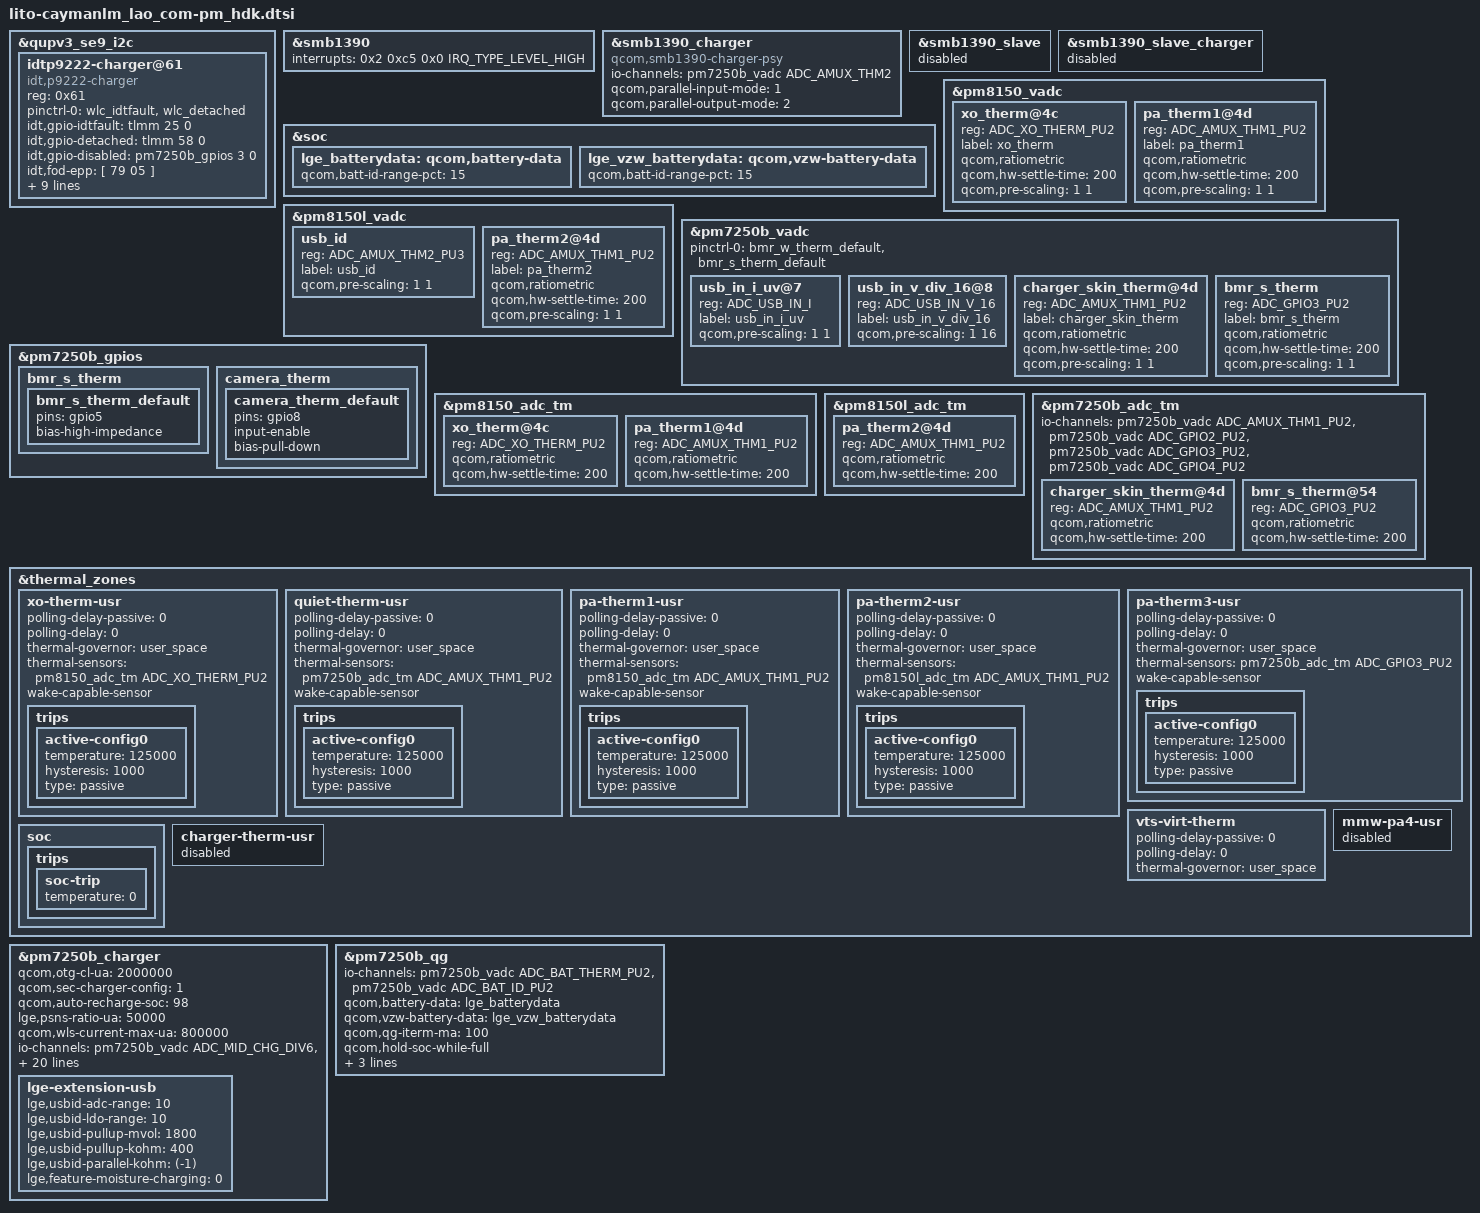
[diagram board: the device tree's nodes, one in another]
// SPDX-License-Identifier: GPL-2.0-only
/*
 * Copyright (c) 2018-2019, The Linux Foundation. All rights reserved.
 */

#include "../lito-caymanlm_common/lito-caymanlm_common-pm.dtsi"

&qupv3_se9_i2c {
	status = "ok";
	#include "../../../qcom/smb1390.dtsi"
};

&smb1390 {
	/delete-property/ interrupts;
	interrupts = <0x2 0xc5 0x0 IRQ_TYPE_LEVEL_HIGH>;
	status = "ok";
};

&smb1390_charger {
	compatible = "qcom,smb1390-charger-psy";
	io-channels = <&pm7250b_vadc ADC_AMUX_THM2>;
	io-channel-names = "cp_die_temp";
	qcom,parallel-input-mode = <1>; /* USBIN */
	qcom,parallel-output-mode = <2>; /* VBAT */
	status = "ok";
};

&smb1390_slave {
	status = "disabled";
};

&smb1390_slave_charger {
	status = "disabled";
};

&soc {
    lge_batterydata: qcom,battery-data {
        qcom,batt-id-range-pct = <15>;
        #include "../../battery_profile/LGE_BLT44_LGC_3450mAh.dtsi"
        #include "../../battery_profile/LGE_BLT47_ATL_4300mAh.dtsi"
        #include "../../battery_profile/LGE_BLT47F_ATL_4300mAh.dtsi"
        #include "../../battery_profile/LGE_BLT47_LGC_4300mAh.dtsi"
    };

     lge_vzw_batterydata: qcom,vzw-battery-data {
        qcom,batt-id-range-pct = <15>;
        #include "../../battery_profile/LGE_BLT47F_LGC_4000mAh.dtsi"
        #include "../../battery_profile/LGE_BLT47_LGC_4000mAh.dtsi"
    };
};

&pm8150_vadc {
	xo_therm@4c {
		reg = <ADC_XO_THERM_PU2>;
		label = "xo_therm";
		qcom,ratiometric;
		qcom,hw-settle-time = <200>;
		qcom,pre-scaling = <1 1>;
	};

	pa_therm1@4d {
		reg = <ADC_AMUX_THM1_PU2>;
		label = "pa_therm1";
		qcom,ratiometric;
		qcom,hw-settle-time = <200>;
		qcom,pre-scaling = <1 1>;
	};
};

&pm8150l_vadc {
    usb_id {
        reg = <ADC_AMUX_THM2_PU3>;
        label = "usb_id";
        qcom,pre-scaling = <1 1>;
    };

	pa_therm2@4d {
		reg = <ADC_AMUX_THM1_PU2>;
		label = "pa_therm2";
		qcom,ratiometric;
		qcom,hw-settle-time = <200>;
		qcom,pre-scaling = <1 1>;
	};
};

&pm7250b_vadc {
    pinctrl-0 = <
        &bmr_w_therm_default
        &bmr_s_therm_default
    >;

    usb_in_i_uv@7 {
        reg = <ADC_USB_IN_I>;
        label = "usb_in_i_uv";
        qcom,pre-scaling = <1 1>;
    };

    usb_in_v_div_16@8 {
        reg = <ADC_USB_IN_V_16>;
        label = "usb_in_v_div_16";
        qcom,pre-scaling = <1 16>;
    };

	/* quiet_therm */
	charger_skin_therm@4d {
		reg = <ADC_AMUX_THM1_PU2>;
		label = "charger_skin_therm";
		qcom,ratiometric;
		qcom,hw-settle-time = <200>;
		qcom,pre-scaling = <1 1>;
	};

	/* pa_therm3 */
	bmr_s_therm {
		reg = <ADC_GPIO3_PU2>;
		label = "bmr_s_therm";
		qcom,ratiometric;
		qcom,hw-settle-time = <200>;
		qcom,pre-scaling = <1 1>;
	};
};

&pm7250b_gpios {
    bmr_s_therm {
        bmr_s_therm_default: bmr_s_therm_default {
            pins = "gpio5";
            bias-high-impedance;
        };
    };
    camera_therm {
		camera_therm_default: camera_therm_default {
			pins = "gpio8";
			input-enable;
			bias-pull-down;
		};
	};
};

&pm8150_adc_tm {
	xo_therm@4c {
		reg = <ADC_XO_THERM_PU2>;
		qcom,ratiometric;
		qcom,hw-settle-time = <200>;
	};

	pa_therm1@4d {
		reg = <ADC_AMUX_THM1_PU2>;
		qcom,ratiometric;
		qcom,hw-settle-time = <200>;
	};
};

&pm8150l_adc_tm {
	pa_therm2@4d {
		reg = <ADC_AMUX_THM1_PU2>;
		qcom,ratiometric;
		qcom,hw-settle-time = <200>;
	};
};

&pm7250b_adc_tm {
	io-channels = <&pm7250b_vadc ADC_AMUX_THM1_PU2>,
			<&pm7250b_vadc ADC_GPIO2_PU2>,
			<&pm7250b_vadc ADC_GPIO3_PU2>,
			<&pm7250b_vadc ADC_GPIO4_PU2>;

	/* quiet_therm */
	charger_skin_therm@4d {
		reg = <ADC_AMUX_THM1_PU2>;
		qcom,ratiometric;
		qcom,hw-settle-time = <200>;
	};

	/* pa_therm3 */
	bmr_s_therm@54 {
		reg = <ADC_GPIO3_PU2>;
		qcom,ratiometric;
		qcom,hw-settle-time = <200>;
	};
};

&thermal_zones {
	xo-therm-usr {
		polling-delay-passive = <0>;
		polling-delay = <0>;
		thermal-governor = "user_space";
		thermal-sensors = <&pm8150_adc_tm ADC_XO_THERM_PU2>;
		wake-capable-sensor;
		trips {
			active-config0 {
				temperature = <125000>;
				hysteresis = <1000>;
				type = "passive";
			};
		};
	};

	quiet-therm-usr {
		polling-delay-passive = <0>;
		polling-delay = <0>;
		thermal-governor = "user_space";
		thermal-sensors = <&pm7250b_adc_tm ADC_AMUX_THM1_PU2>;
		wake-capable-sensor;
		trips {
			active-config0 {
				temperature = <125000>;
				hysteresis = <1000>;
				type = "passive";
			};
		};
	};

	pa-therm1-usr {
		polling-delay-passive = <0>;
		polling-delay = <0>;
		thermal-governor = "user_space";
		thermal-sensors = <&pm8150_adc_tm ADC_AMUX_THM1_PU2>;
		wake-capable-sensor;
		trips {
			active-config0 {
				temperature = <125000>;
				hysteresis = <1000>;
				type = "passive";
			};
		};
	};

	pa-therm2-usr {
		polling-delay-passive = <0>;
		polling-delay = <0>;
		thermal-governor = "user_space";
		thermal-sensors = <&pm8150l_adc_tm ADC_AMUX_THM1_PU2>;
		wake-capable-sensor;
		trips {
			active-config0 {
				temperature = <125000>;
				hysteresis = <1000>;
				type = "passive";
			};
		};
	};

	pa-therm3-usr {
		polling-delay-passive = <0>;
		polling-delay = <0>;
		thermal-governor = "user_space";
		thermal-sensors = <&pm7250b_adc_tm ADC_GPIO3_PU2>;
		wake-capable-sensor;
		trips {
		active-config0 {
			temperature = <125000>;
			hysteresis = <1000>;
			type = "passive";
		};
		};
	};

	vts-virt-therm {
		polling-delay-passive = <0>;
		polling-delay = <0>;
		thermal-governor = "user_space";
	};

	soc {
		trips {
			soc-trip {
				temperature = <0>;
			};
		};
	};

	charger-therm-usr {
		status = "disabled";
	};

	mmw-pa4-usr {
		status = "disabled";
	};
};

&pm7250b_charger {
    status = "ok";
    qcom,otg-cl-ua=<2000000>;
    qcom,sec-charger-config = <1>;
    qcom,auto-recharge-soc = <98>;
    lge,psns-ratio-ua = <50000>;
    qcom,wls-current-max-ua = <800000>;
    io-channels = <&pm7250b_vadc ADC_MID_CHG_DIV6>,
              <&pm7250b_vadc ADC_USB_IN_V_16>,
              <&pm7250b_vadc ADC_USB_IN_I>,
              <&pm7250b_vadc ADC_CHG_TEMP>,
              <&pm7250b_vadc ADC_DIE_TEMP>,
              <&pm7250b_vadc ADC_AMUX_THM3_PU2>,
              <&pm7250b_vadc ADC_SBUx>,
              <&pm7250b_vadc ADC_VPH_PWR>,
              <&pm8150l_vadc ADC_AMUX_THM2_PU3>;
    io-channel-names = "mid_voltage",
               "usb_in_voltage",
               "usb_in_current",
               "chg_temp",
               "die_temp",
               "conn_temp",
               "sbux_res",
               "vph_voltage",
               "usb_id";
    qcom,battery-data = <&lge_batterydata>;
    qcom,vzw-wbattery-data = <&lge_vzw_batterydata>;
    qcom,step-charging-enable;
    /delete-property/ qcom,sw-jeita-enable;
    qcom,charger-temp-max = <800>;
    qcom,smb-temp-max = <800>;
    qcom,suspend-input-on-debug-batt;
    qcom,fcc-stepping-enable;
    lge,vconn-boost-en = <&pm7250b_gpios 11 GPIO_ACTIVE_HIGH>;
    lge,prot-overchg-ent-dischg-off-uv = <10000>;
    lge,prot-overchg-ent-chg-off-uv = <20000>;
    lge,prot-overchg-rel-off-uv = <50000>;

    lge-extension-usb {
        lge,usbid-adc-range = <10>;		// ADC margin (pct unit)
        lge,usbid-ldo-range = <10>;		// LDO margin (pct unit)
        lge,usbid-pullup-mvol = <1800>;		// Pull-up voltage
        lge,usbid-pullup-kohm = <400>;		// Pull-up resistance
        lge,usbid-parallel-kohm = <(-1)>;	// Pull-up resistance

        lge,feature-moisture-charging = <0>;
    };
};

&pm7250b_qg {
    status = "ok";
    io-channels = <&pm7250b_vadc ADC_BAT_THERM_PU2>,
              <&pm7250b_vadc ADC_BAT_ID_PU2>;
    io-channel-names = "batt-therm",
               "batt-id";
    qcom,battery-data = <&lge_batterydata>;
    qcom,vzw-battery-data = <&lge_vzw_batterydata>;
    qcom,qg-iterm-ma = <100>;
    qcom,hold-soc-while-full;
    qcom,linearize-soc;
    qcom,cl-feedback-on;
    qcom,cl-min-start-soc = <0>;
};

&qupv3_se9_i2c {
	idtp9222-charger@61 {				// Slave driver and slave Address
		compatible ="idt,p9222-charger";	// Manufacture, model
		reg = <0x61>;				// Slave Address
		status = "ok";

		// one time calling of pinctrl.
		// pinctrl-0 is the permanent configuraion of MSM GPIOs
		pinctrl-names = "wlc_pinctrl";
		pinctrl-0 = <&wlc_idtfault &wlc_detached>;

		idt,gpio-idtfault = <&tlmm 25 0>;
		idt,gpio-detached = <&tlmm 58 0>;
		idt,gpio-disabled = <&pm7250b_gpios 3 0>;

		// FOD parameters
		idt,fod-epp = [
			79 05
		];

		idt,configure-bppcurr = <750000>;
		idt,configure-eppcurr = <800000>;
		idt,configure-fullcurr = <500000>;
		idt,configure-bppvolt = <6000000>;
		idt,configure-eppvolt = <9000000>;
		idt,configure-overheat = <450>;		// Temperature threshold to send EPT_BY_OVERTEMP
		idt,configure-sysfs;			// For debug sysfs
		idt,configure-dualdisplay;
		idt,configure-charge-done;
	};
};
